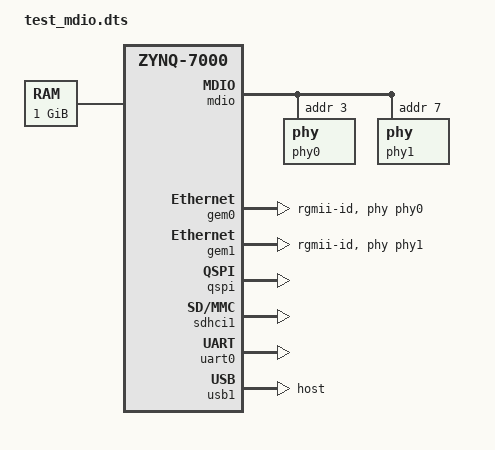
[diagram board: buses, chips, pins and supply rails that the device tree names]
/*
 * CAUTION: This file is automatically generated by Xilinx.
 * Version:  
 * Today is: Tue Aug 15 22:44:01 2017
*/


/dts-v1/;
/include/ "zynq-7000.dtsi"
/include/ "pl.dtsi"
/ {
	cpus {
		cpu@0 {
			operating-points = <500000 1000000 250000 1000000>;
		};
	};
	chosen {
		bootargs = "console=ttyPS0,115200";
	};
	aliases {
		ethernet0 = &gem0;
		ethernet1 = &gem1;
		serial0 = &uart0;
		serial1 = &axi_uart16550_2;
		serial2 = &axi_uart16550_3;
		serial3 = &axi_uart16550_4;
		serial4 = &axi_uart16550_5;
		serial5 = &axi_uart16550_6;
		serial6 = &axi_uart16550_7;
		serial7 = &axi_uart16550_0;
		serial8 = &axi_uart16550_1;
		spi0 = &qspi;
	};
	memory {
		device_type = "memory";
		reg = <0x0 0x40000000>;
	};

    	mdio {
         compatible = "cdns,macb-mdio";
         reg = <0xe000b000 0x1000>;
         clocks = <&clkc 30>, <&clkc 30>, <&clkc 13>;
         clock-names = "pclk", "hclk", "tx_clk";
         #address-cells = <1>;
         #size-cells = <0>;
         phy0: phy@3 {
              device_type = "ethernet-phy";
              reg = <3>;
         	    } ;
         phy1: phy@7 {
              device_type = "ethernet-phy";
              reg = <7>;
                    } ;
       };
};
&gem0 {
	local-mac-address = [00 0a 35 00 00 00];
	phy-mode = "rgmii-id";
	status = "okay";
	xlnx,ptp-enet-clock = <0x4f790d8>;
	phy-handle = <&phy0>;
};
&gem1 {
	local-mac-address = [00 0a 35 00 00 05];
	phy-mode = "rgmii-id";
	status = "okay";
	xlnx,ptp-enet-clock = <0x4f790d8>;
	phy-handle = <&phy1>;
};
&gpio0 {
	emio-gpio-width = <42>;
	gpio-mask-high = <0x0>;
	gpio-mask-low = <0x5600>;
};
&intc {
	num_cpus = <2>;
	num_interrupts = <96>;
};
&qspi {
	is-dual = <0>;
	num-cs = <1>;
	status = "okay";
};
&sdhci1 {
	status = "okay";
	xlnx,has-cd = <0x1>;
	xlnx,has-power = <0x0>;
	xlnx,has-wp = <0x0>;
};
&uart0 {
	device_type = "serial";
	port-number = <0>;
	status = "okay";
};
&usb1 {
	dr_mode = "host";
	phy_type = "ulpi";
	status = "okay";
};
&clkc {
	fclk-enable = <0xf>;
	ps-clk-frequency = <50000000>;
};
